VERSION ""

NS_ :

BS_:

BU_: XXX

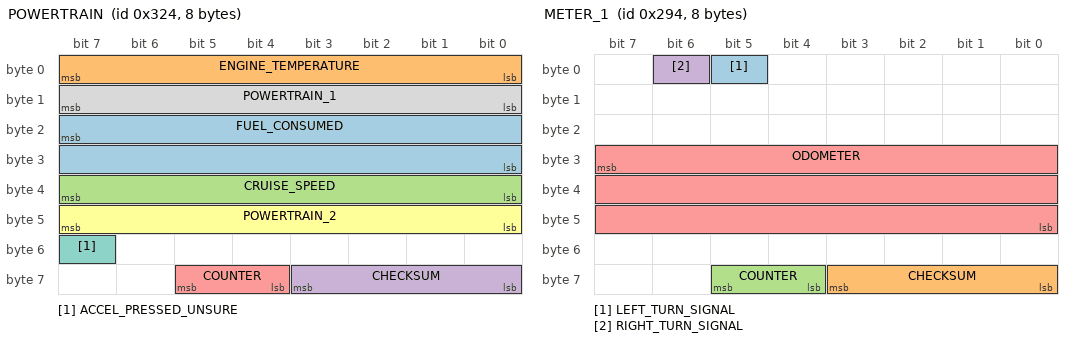
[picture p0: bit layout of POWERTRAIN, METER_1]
BO_ 804 POWERTRAIN: 8 XXX
 SG_ FUEL_CONSUMED : 23|16@0+ (1,0) [0|65535] "" XXX
 SG_ ENGINE_TEMPERATURE : 7|8@0+ (1,0) [0|255] "Degrees Celsius" XXX
 SG_ CRUISE_SPEED : 39|8@0+ (1,0) [0|255] "km/h" XXX
 SG_ CHECKSUM : 59|4@0+ (1,0) [0|15] "" XXX
 SG_ COUNTER : 61|2@0+ (1,0) [0|3] "" XXX
 SG_ POWERTRAIN_2 : 47|8@0- (1,0) [0|255] "" XXX
 SG_ ACCEL_PRESSED_UNSURE : 55|1@0+ (1,0) [0|255] "" XXX
 SG_ POWERTRAIN_1 : 15|8@0+ (1,0) [0|255] "" XXX

BO_ 660 METER_1: 8 XXX
 SG_ LEFT_TURN_SIGNAL : 5|1@0+ (1,0) [0|1] "" XXX
 SG_ CHECKSUM : 59|4@0+ (1,0) [0|15] "" XXX
 SG_ COUNTER : 61|2@0+ (1,0) [0|3] "" XXX
 SG_ RIGHT_TURN_SIGNAL : 6|1@0+ (1,0) [0|1] "" XXX
 SG_ ODOMETER : 31|24@0+ (1,0) [0|16777215] "km" XXX

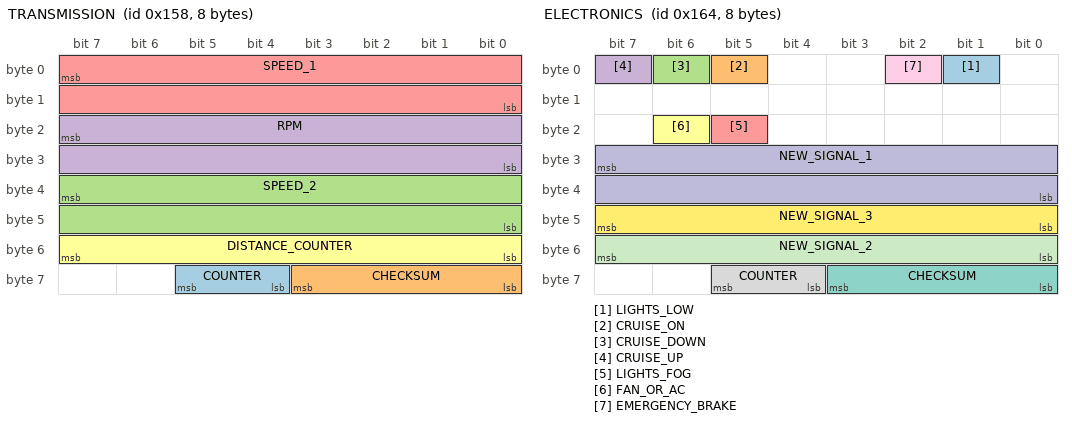
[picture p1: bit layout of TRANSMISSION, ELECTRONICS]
BO_ 344 TRANSMISSION: 8 XXX
 SG_ COUNTER : 61|2@0+ (1,0) [0|3] "" XXX
 SG_ CHECKSUM : 59|4@0+ (1,0) [0|15] "" XXX
 SG_ SPEED_2 : 39|16@0+ (0.01,0) [0|65535] "km/h" XXX
 SG_ RPM : 23|16@0+ (1,0) [0|65535] "" XXX
 SG_ SPEED_1 : 7|16@0+ (0.01,0) [0|65535] "km/h" XXX
 SG_ DISTANCE_COUNTER : 55|8@0+ (0.01,0) [0|255] "km" XXX

BO_ 356 ELECTRONICS: 8 XXX
 SG_ LIGHTS_LOW : 1|1@0+ (1,0) [0|1] "" XXX
 SG_ CRUISE_ON : 5|1@0+ (1,0) [0|1] "" XXX
 SG_ CRUISE_DOWN : 6|1@0+ (1,0) [0|1] "" XXX
 SG_ CRUISE_UP : 7|1@0+ (1,0) [0|1] "" XXX
 SG_ LIGHTS_FOG : 21|1@0+ (1,0) [0|1] "" XXX
 SG_ FAN_OR_AC : 22|1@0+ (1,0) [0|1] "" XXX
 SG_ CHECKSUM : 59|4@0+ (1,0) [0|15] "" XXX
 SG_ COUNTER : 61|2@0+ (1,0) [0|3] "" XXX
 SG_ EMERGENCY_BRAKE : 2|1@0+ (1,0) [0|1] "" XXX
 SG_ NEW_SIGNAL_1 : 31|16@0+ (1,0) [0|65535] "" XXX
 SG_ NEW_SIGNAL_2 : 55|8@0+ (1,0) [0|255] "" XXX
 SG_ NEW_SIGNAL_3 : 47|8@0+ (1,0) [0|255] "" XXX

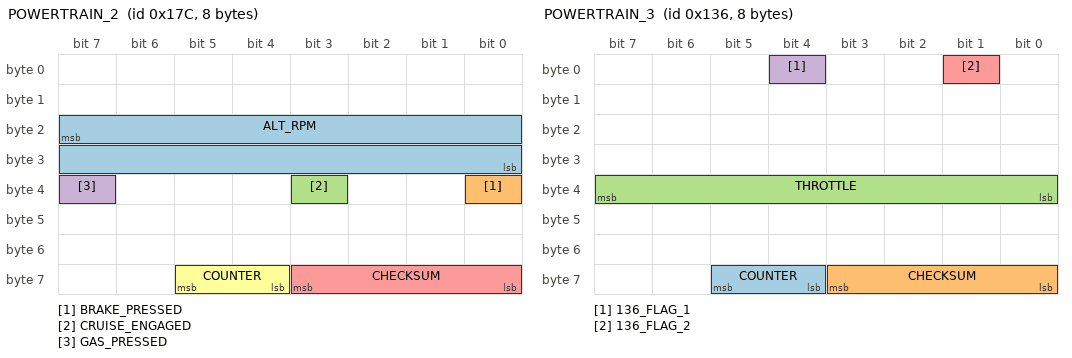
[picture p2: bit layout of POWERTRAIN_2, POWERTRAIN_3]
BO_ 380 POWERTRAIN_2: 8 XXX
 SG_ ALT_RPM : 23|16@0+ (1,0) [0|65535] "" XXX
 SG_ BRAKE_PRESSED : 32|1@0+ (1,0) [0|1] "" XXX
 SG_ CRUISE_ENGAGED : 35|1@0+ (1,0) [0|1] "" XXX
 SG_ GAS_PRESSED : 39|1@0+ (1,0) [0|1] "" XXX
 SG_ CHECKSUM : 59|4@0+ (1,0) [0|15] "" XXX
 SG_ COUNTER : 61|2@0+ (1,0) [0|3] "" XXX

BO_ 392 NEW_MSG_1: 6 XXX
 SG_ COUNTER : 45|2@0+ (1,0) [0|3] "" XXX
 SG_ CHECKSUM : 43|4@0+ (1,0) [0|15] "" XXX

BO_ 229 NEW_MSG_2: 4 XXX
 SG_ COUNTER : 29|2@0+ (1,0) [0|3] "" XXX
 SG_ CHECKSUM : 27|4@0+ (1,0) [0|15] "" XXX

BO_ 310 POWERTRAIN_3: 8 XXX
 SG_ COUNTER : 61|2@0+ (1,0) [0|3] "" XXX
 SG_ CHECKSUM : 59|4@0+ (1,0) [0|15] "" XXX
 SG_ THROTTLE : 39|8@0+ (1,0) [0|255] "" XXX
 SG_ 136_FLAG_1 : 4|1@0+ (1,0) [0|1] "" XXX
 SG_ 136_FLAG_2 : 1|1@0+ (1,0) [0|1] "" XXX

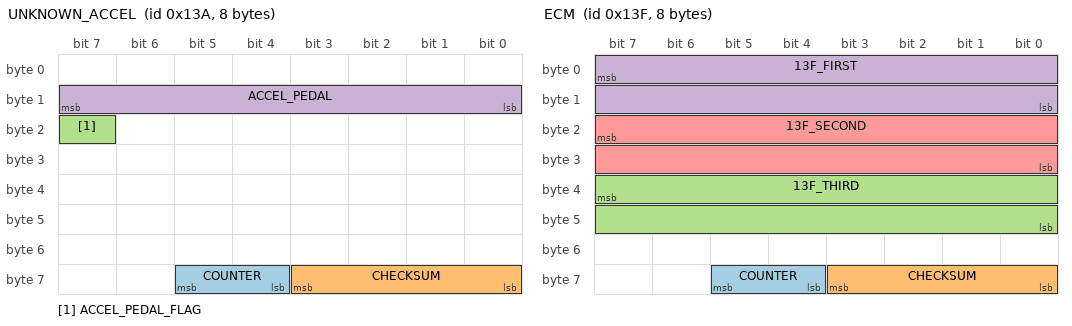
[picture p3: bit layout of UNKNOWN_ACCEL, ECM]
BO_ 314 UNKNOWN_ACCEL: 8 XXX
 SG_ COUNTER : 61|2@0+ (1,0) [0|3] "" XXX
 SG_ CHECKSUM : 59|4@0+ (1,0) [0|15] "" XXX
 SG_ ACCEL_PEDAL_FLAG : 23|1@0+ (1,0) [0|1] "" XXX
 SG_ ACCEL_PEDAL : 15|8@0+ (1,0) [0|255] "" XXX

BO_ 319 ECM: 8 XXX
 SG_ COUNTER : 61|2@0+ (1,0) [0|3] "" XXX
 SG_ CHECKSUM : 59|4@0+ (1,0) [0|15] "" XXX
 SG_ 13F_THIRD : 39|16@0- (1,0) [0|65535] "" XXX
 SG_ 13F_FIRST : 7|16@0- (1,0) [0|65535] "" XXX
 SG_ 13F_SECOND : 23|16@0- (1,0) [0|65535] "" XXX

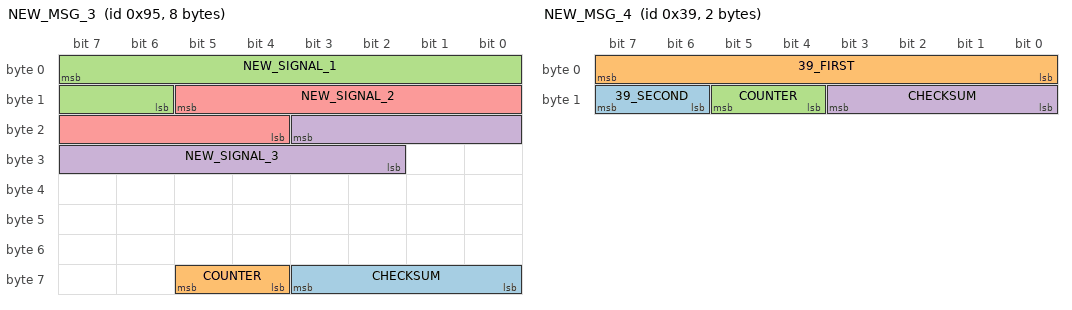
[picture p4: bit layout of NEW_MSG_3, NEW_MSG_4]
BO_ 149 NEW_MSG_3: 8 XXX
 SG_ CHECKSUM : 59|4@0+ (1,0) [0|15] "" XXX
 SG_ COUNTER : 61|2@0+ (1,0) [0|3] "" XXX
 SG_ NEW_SIGNAL_1 : 7|10@0+ (1,0) [0|1023] "" XXX
 SG_ NEW_SIGNAL_3 : 19|10@0+ (1,0) [0|1023] "" XXX
 SG_ NEW_SIGNAL_2 : 13|10@0+ (1,0) [0|255] "" XXX

BO_ 57 NEW_MSG_4: 2 XXX
 SG_ 39_SECOND : 15|2@0+ (1,0) [0|3] "" XXX
 SG_ 39_FIRST : 7|8@0+ (1,0) [0|255] "" XXX
 SG_ COUNTER : 13|2@0+ (1,0) [0|3] "" XXX
 SG_ CHECKSUM : 11|4@0+ (1,0) [0|15] "" XXX

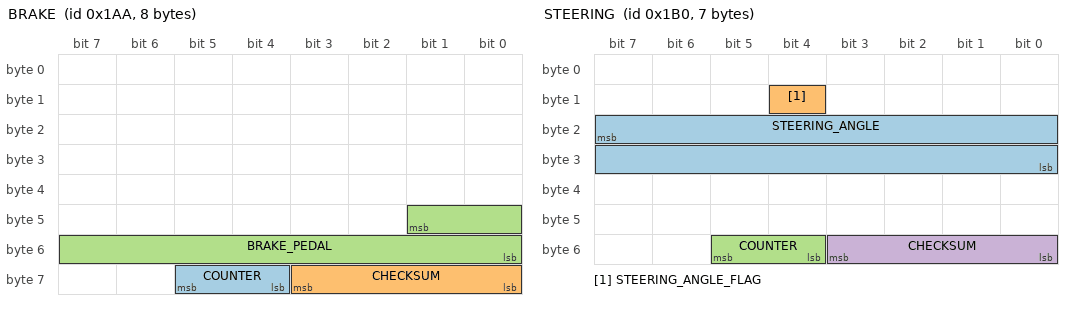
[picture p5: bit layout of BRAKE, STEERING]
BO_ 426 BRAKE: 8 XXX
 SG_ COUNTER : 61|2@0+ (1,0) [0|3] "" XXX
 SG_ CHECKSUM : 59|4@0+ (1,0) [0|15] "" XXX
 SG_ BRAKE_PEDAL : 41|10@0+ (0.01,0) [0|4095] "" XXX

BO_ 432 STEERING: 7 XXX
 SG_ STEERING_ANGLE : 23|16@0- (1,0) [0|65535] "" XXX
 SG_ STEERING_ANGLE_FLAG : 12|1@0+ (1,0) [0|65535] "" XXX
 SG_ COUNTER : 53|2@0+ (1,0) [0|3] "" XXX
 SG_ CHECKSUM : 51|4@0+ (1,0) [0|15] "" XXX

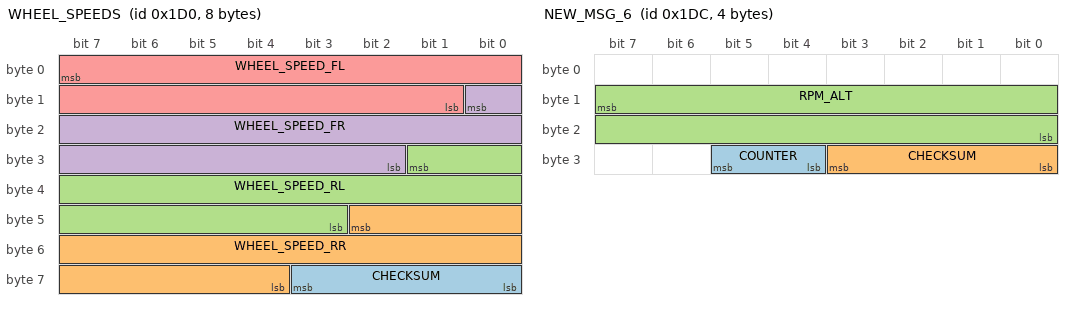
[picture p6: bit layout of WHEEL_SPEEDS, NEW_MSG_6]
BO_ 464 WHEEL_SPEEDS: 8 XXX
 SG_ CHECKSUM : 59|4@0+ (1,0) [0|15] "" XXX
 SG_ WHEEL_SPEED_RR : 42|15@0+ (0.002759506,0) [0|524287] "m/s" XXX
 SG_ WHEEL_SPEED_RL : 25|15@0+ (0.002759506,0) [0|8191] "m/s" XXX
 SG_ WHEEL_SPEED_FR : 8|15@0+ (0.002759506,0) [0|16383] "m/s" XXX
 SG_ WHEEL_SPEED_FL : 7|15@0- (0.002759506,0) [0|32767] "m/s" XXX

BO_ 420 NEW_MSG_5: 8 XXX
 SG_ COUNTER : 61|2@0+ (1,0) [0|3] "" XXX
 SG_ CHECKSUM : 59|4@0+ (1,0) [0|15] "" XXX

BO_ 476 NEW_MSG_6: 4 XXX
 SG_ COUNTER : 29|2@0+ (1,0) [0|3] "" XXX
 SG_ CHECKSUM : 27|4@0+ (1,0) [0|15] "" XXX
 SG_ RPM_ALT : 15|16@0+ (1,0) [0|65535] "" XXX

BO_ 819 NEW_MSG_7: 7 XXX
 SG_ CHECKSUM : 51|4@0+ (1,0) [0|15] "" XXX
 SG_ COUNTER : 53|2@0+ (1,0) [0|3] "" XXX

BO_ 884 METER_2: 7 XXX
 SG_ COUNTER : 53|2@0+ (1,0) [0|3] "" XXX
 SG_ CHECKSUM : 51|4@0+ (1,0) [0|15] "" XXX

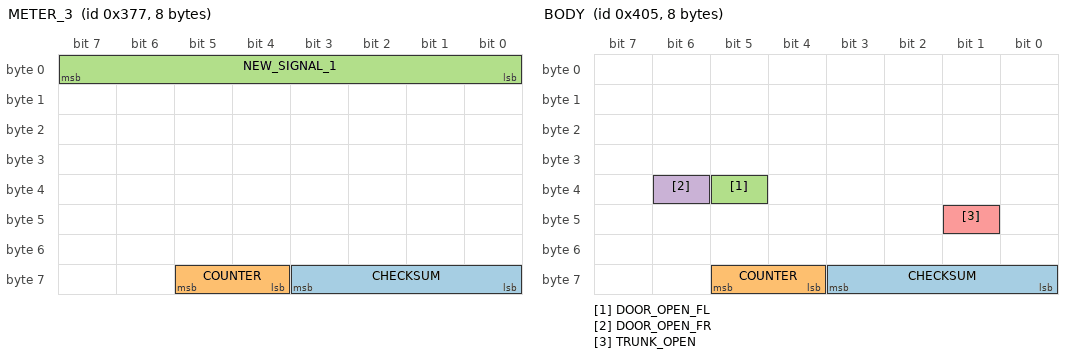
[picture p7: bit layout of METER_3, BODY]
BO_ 887 METER_3: 8 XXX
 SG_ CHECKSUM : 59|4@0+ (1,0) [0|15] "" XXX
 SG_ COUNTER : 61|2@0+ (1,0) [0|3] "" XXX
 SG_ NEW_SIGNAL_1 : 7|8@0+ (1,0) [0|255] "" XXX

BO_ 888 METER_4: 8 XXX
 SG_ CHECKSUM : 59|4@0+ (1,0) [0|15] "" XXX
 SG_ COUNTER : 61|2@0+ (1,0) [0|3] "" XXX

BO_ 773 NEW_MSG_8: 2 XXX
 SG_ COUNTER : 13|2@0+ (1,0) [0|3] "" XXX
 SG_ CHECKSUM : 11|4@0+ (1,0) [0|15] "" XXX

BO_ 963 NEW_MSG_9: 8 XXX
 SG_ CHECKSUM : 59|4@0+ (1,0) [0|15] "" XXX
 SG_ COUNTER : 61|2@0+ (1,0) [0|3] "" XXX

BO_ 965 NEW_MSG_10: 8 XXX
 SG_ CHECKSUM : 59|4@0+ (1,0) [0|15] "" XXX
 SG_ COUNTER : 61|2@0+ (1,0) [0|3] "" XXX

BO_ 966 NEW_MSG_11: 8 XXX
 SG_ CHECKSUM : 59|4@0+ (1,0) [0|15] "" XXX
 SG_ COUNTER : 61|2@0+ (1,0) [0|3] "" XXX

BO_ 967 NEW_MSG_12: 8 XXX
 SG_ CHECKSUM : 59|4@0+ (1,0) [0|15] "" XXX
 SG_ COUNTER : 61|2@0+ (1,0) [0|3] "" XXX

BO_ 983 NEW_MSG_13: 8 XXX
 SG_ CHECKSUM : 59|4@0+ (1,0) [0|15] "" XXX
 SG_ COUNTER : 61|2@0+ (1,0) [0|3] "" XXX

BO_ 1029 BODY: 8 XXX
 SG_ CHECKSUM : 59|4@0+ (1,0) [0|15] "" XXX
 SG_ COUNTER : 61|2@0+ (1,0) [0|3] "" XXX
 SG_ DOOR_OPEN_FL : 37|1@0+ (1,0) [0|1] "" XXX
 SG_ DOOR_OPEN_FR : 38|1@0+ (1,0) [0|1] "" XXX
 SG_ TRUNK_OPEN : 41|1@0+ (1,0) [0|1] "" XXX

BO_ 1036 NEW_MSG_15: 8 XXX
 SG_ CHECKSUM : 59|4@0+ (1,0) [0|15] "" XXX
 SG_ COUNTER : 61|2@0+ (1,0) [0|3] "" XXX

BO_ 1064 NEW_MSG_16: 7 XXX
 SG_ COUNTER : 53|2@0+ (1,0) [0|3] "" XXX
 SG_ CHECKSUM : 51|4@0+ (1,0) [0|15] "" XXX

BO_ 1108 NEW_MSG_17: 6 XXX
 SG_ COUNTER : 45|2@0+ (1,0) [0|3] "" XXX
 SG_ CHECKSUM : 43|4@0+ (1,0) [0|15] "" XXX

BO_ 1729 NEW_MSG_18: 1 XXX
 SG_ COUNTER : 5|2@0+ (1,0) [0|3] "" XXX
 SG_ CHECKSUM : 3|4@0+ (1,0) [0|15] "" XXX

CM_ SG_ 319 13F_THIRD "Always increments of 10";
CM_ SG_ 426 BRAKE_PEDAL "0x069 minimum, 0x2FF maximum";
CM_ SG_ 432 STEERING_ANGLE_FLAG "Seems to be triggered when STEERING_ANGLE is below 195";
